# STM32N647 register map
File version: 1.0
CPU: CM55 r0p1, little endian, no MPU, FPU, vendor SysTick, 8 interrupt priority bits
Registers are 32-bit, read-write, reset 0x0 unless marked. A register's access mark holds for its fields unless they carry their own. Offsets are from the block's base; [hi:lo] are bit positions; {n}, {i} and the like mark numbered series.

## RCC (part 2 of 2) — Reset and clock control
Base 0x46028000
Same registers: RCC_S 0x56028000
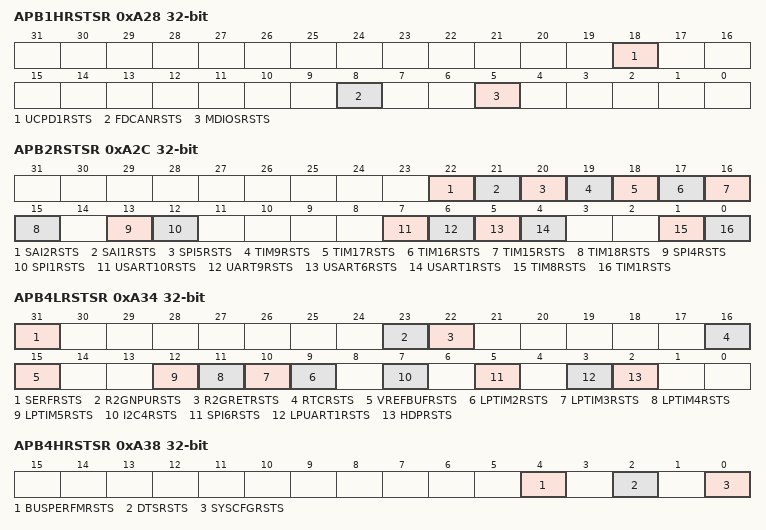
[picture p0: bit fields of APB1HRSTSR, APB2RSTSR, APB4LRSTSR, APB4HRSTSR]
0xA28 APB1HRSTSR wo — RCC APB1H reset register
  [18] UCPD1RSTS — UCPD1 reset
  [8] FDCANRSTS — FDCAN reset
  [5] MDIOSRSTS — MDIOS reset
0xA2C APB2RSTSR wo — RCC APB2 reset register
  [22] SAI2RSTS — SAI2 reset
  [21] SAI1RSTS — SAI1 reset
  [20] SPI5RSTS — SPI5 reset
  [19] TIM9RSTS — TIM9 reset
  [18] TIM17RSTS — TIM17 reset
  [17] TIM16RSTS — TIM16 reset
  [16] TIM15RSTS — TIM15 reset
  [15] TIM18RSTS — TIM18 reset
  [13] SPI4RSTS — SPI4 reset
  [12] SPI1RSTS — SPI1 reset
  [7] USART10RSTS — USART10 reset
  [6] UART9RSTS — UART9 reset
  [5] USART6RSTS — USART6 reset
  [4] USART1RSTS — USART1 reset
  [1] TIM8RSTS — TIM8 reset
  [0] TIM1RSTS — TIM1 reset
0xA34 APB4LRSTSR wo — RCC APB4L reset register
  [31] SERFRSTS — SERF reset
  [23] R2GNPURSTS — R2GNPU reset
  [22] R2GRETRSTS — R2GRET reset
  [16] RTCRSTS — RTC reset
  [15] VREFBUFRSTS — VREFBUF reset
  [n+7] LPTIM{n}RSTS (n=2..5) — LPTIM{n} reset
  [7] I2C4RSTS — I2C4 reset
  [5] SPI6RSTS — SPI6 reset
  [3] LPUART1RSTS — LPUART1 reset
  [2] HDPRSTS — HDP reset
0xA38 APB4HRSTSR wo — RCC APB4H reset register
  [4] BUSPERFMRSTS — BUSPERFM reset
  [2] DTSRSTS — DTS reset
  [0] SYSCFGRSTS — SYSCFG reset
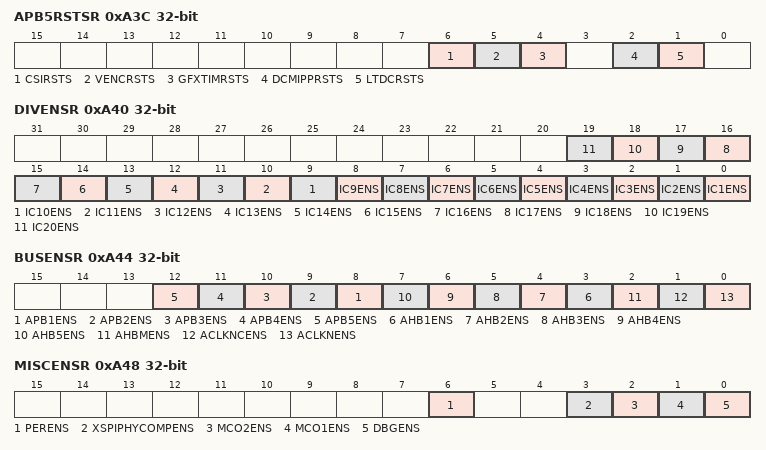
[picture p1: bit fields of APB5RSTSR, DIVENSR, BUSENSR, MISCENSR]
0xA3C APB5RSTSR wo — RCC APB5 reset register
  [6] CSIRSTS — CSI reset
  [5] VENCRSTS — VENC reset
  [4] GFXTIMRSTS — GFXTIM reset
  [2] DCMIPPRSTS — DCMIPP reset
  [1] LTDCRSTS — LTDC reset
0xA40 DIVENSR wo — RCC Divider enable register
  [n-1] IC{n}ENS (n=1..20) — IC{n} enable
0xA44 BUSENSR wo — RCC bus enable register
  [n+7] APB{n}ENS (n=1..5) — APB{n} enable
  [n+2] AHB{n}ENS (n=1..5) — AHB{n} enable
  [2] AHBMENS — AHBM enable
  [1] ACLKNCENS — ACLKNC enable
  [0] ACLKNENS — ACLKN enable
0xA48 MISCENSR wo — RCC miscellaneous enable register
  [6] PERENS — PER enable
  [3] XSPIPHYCOMPENS — XSPIPHYCOMP enable
  [2] MCO2ENS — MCO2 enable
  [1] MCO1ENS — MCO1 enable
  [0] DBGENS — DBG enable
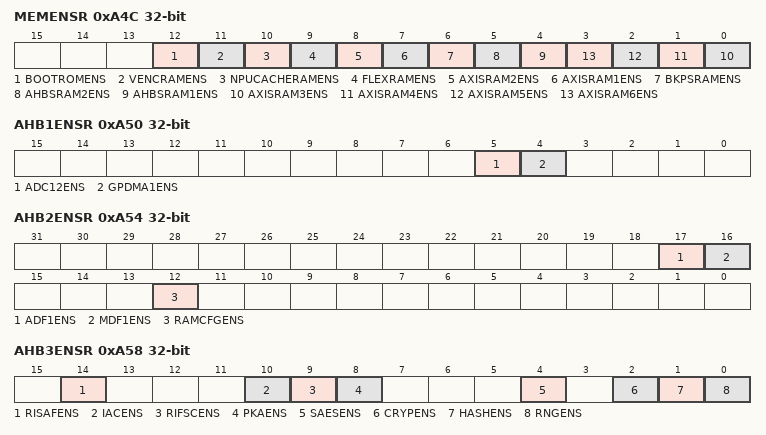
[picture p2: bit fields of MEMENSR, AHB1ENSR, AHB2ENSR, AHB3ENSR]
0xA4C MEMENSR wo — RCC memory enable register
  [12] BOOTROMENS — BOOTROM enable
  [11] VENCRAMENS — VENCRAM enable
  [10] NPUCACHERAMENS — NPUCACHERAM enable
  [9] FLEXRAMENS — FLEXRAM enable
  [8] AXISRAM2ENS — AXISRAM2 enable
  [7] AXISRAM1ENS — AXISRAM1 enable
  [6] BKPSRAMENS — BKPSRAM enable
  [5] AHBSRAM2ENS — AHBSRAM2 enable
  [4] AHBSRAM1ENS — AHBSRAM1 enable
  [n-3] AXISRAM{n}ENS (n=3..6) — AXISRAM{n} enable
0xA50 AHB1ENSR wo — RCC AHB1 enable register
  [5] ADC12ENS — ADC12 enable
  [4] GPDMA1ENS — GPDMA1 enable
0xA54 AHB2ENSR wo — RCC AHB2 enable register
  [17] ADF1ENS — ADF1 enable
  [16] MDF1ENS — MDF1 enable
  [12] RAMCFGENS — RAMCFG enable
0xA58 AHB3ENSR wo — RCC AHB3 enable register
  [14] RISAFENS — RISAF enable
  [10] IACENS — IAC enable
  [9] RIFSCENS — RIFSC enable
  [8] PKAENS — PKA enable
  [4] SAESENS — SAES enable
  [2] CRYPENS — CRYP enable
  [1] HASHENS — HASH enable
  [0] RNGENS — RNG enable
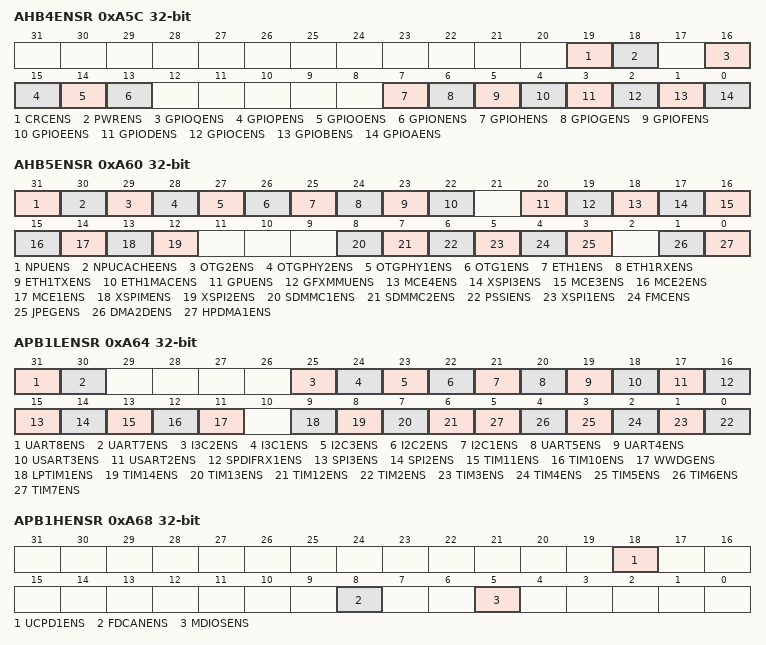
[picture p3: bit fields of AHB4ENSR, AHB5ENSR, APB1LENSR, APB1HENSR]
0xA5C AHB4ENSR wo — RCC AHB4 enable register
  [19] CRCENS — CRC enable
  [18] PWRENS — PWR enable
  [16] GPIOQENS — GPIOQ enable
  [15] GPIOPENS — GPIOP enable
  [14] GPIOOENS — GPIOO enable
  [13] GPIONENS — GPION enable
  [7] GPIOHENS — GPIOH enable
  [6] GPIOGENS — GPIOG enable
  [5] GPIOFENS — GPIOF enable
  [4] GPIOEENS — GPIOE enable
  [3] GPIODENS — GPIOD enable
  [2] GPIOCENS — GPIOC enable
  [1] GPIOBENS — GPIOB enable
  [0] GPIOAENS — GPIOA enable
0xA60 AHB5ENSR wo — RCC AHB5 enable register
  [31] NPUENS — NPU enable
  [30] NPUCACHEENS — NPUCACHE enable
  [29] OTG2ENS — OTG2 enable
  [28] OTGPHY2ENS — OTGPHY2 enable
  [27] OTGPHY1ENS — OTGPHY1 enable
  [26] OTG1ENS — OTG1 enable
  [25] ETH1ENS — ETH1 enable
  [24] ETH1RXENS — ETH1RX enable
  [23] ETH1TXENS — ETH1TX enable
  [22] ETH1MACENS — ETH1MAC enable
  [20] GPUENS — GPU enable
  [19] GFXMMUENS — GFXMMU enable
  [18] MCE4ENS — MCE4 enable
  [17] XSPI3ENS — XSPI3 enable
  [16] MCE3ENS — MCE3 enable
  [15] MCE2ENS — MCE2 enable
  [14] MCE1ENS — MCE1 enable
  [13] XSPIMENS — XSPIM enable
  [12] XSPI2ENS — XSPI2 enable
  [8] SDMMC1ENS — SDMMC1 enable
  [7] SDMMC2ENS — SDMMC2 enable
  [6] PSSIENS — PSSI enable
  [5] XSPI1ENS — XSPI1 enable
  [4] FMCENS — FMC enable
  [3] JPEGENS — JPEG enable
  [1] DMA2DENS — DMA2D enable
  [0] HPDMA1ENS — HPDMA1 enable
0xA64 APB1LENSR wo — RCC APB1L enable register
  [31] UART8ENS — UART8 enable
  [30] UART7ENS — UART7 enable
  [25] I3C2ENS — I3C2 enable
  [24] I3C1ENS — I3C1 enable
  [23] I2C3ENS — I2C3 enable
  [22] I2C2ENS — I2C2 enable
  [21] I2C1ENS — I2C1 enable
  [20] UART5ENS — UART5 enable
  [19] UART4ENS — UART4 enable
  [18] USART3ENS — USART3 enable
  [17] USART2ENS — USART2 enable
  [16] SPDIFRX1ENS — SPDIFRX1 enable
  [15] SPI3ENS — SPI3 enable
  [14] SPI2ENS — SPI2 enable
  [13] TIM11ENS — TIM11 enable
  [12] TIM10ENS — TIM10 enable
  [11] WWDGENS — WWDG enable
  [9] LPTIM1ENS — LPTIM1 enable
  [8] TIM14ENS — TIM14 enable
  [7] TIM13ENS — TIM13 enable
  [6] TIM12ENS — TIM12 enable
  [n-2] TIM{n}ENS (n=2..7) — TIM{n} enable
0xA68 APB1HENSR wo — RCC APB1H enable register
  [18] UCPD1ENS — UCPD1 enable
  [8] FDCANENS — FDCAN enable
  [5] MDIOSENS — MDIOS enable
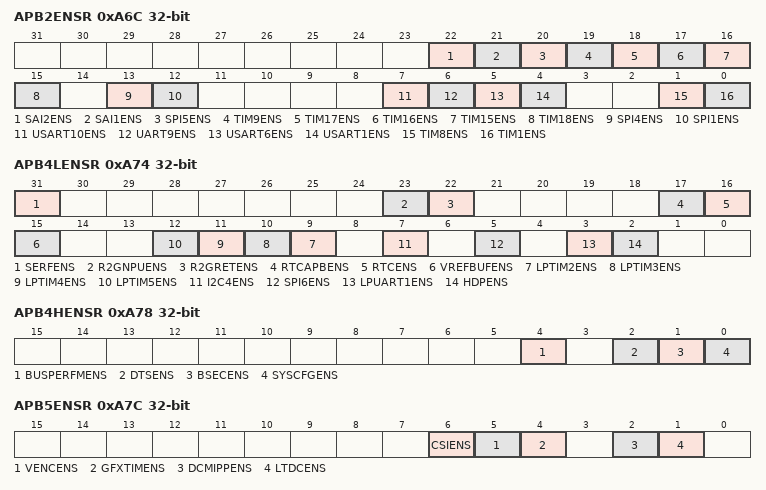
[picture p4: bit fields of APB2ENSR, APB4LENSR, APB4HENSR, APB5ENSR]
0xA6C APB2ENSR wo — RCC APB2 enable register
  [22] SAI2ENS — SAI2 enable
  [21] SAI1ENS — SAI1 enable
  [20] SPI5ENS — SPI5 enable
  [19] TIM9ENS — TIM9 enable
  [18] TIM17ENS — TIM17 enable
  [17] TIM16ENS — TIM16 enable
  [16] TIM15ENS — TIM15 enable
  [15] TIM18ENS — TIM18 enable
  [13] SPI4ENS — SPI4 enable
  [12] SPI1ENS — SPI1 enable
  [7] USART10ENS — USART10 enable
  [6] UART9ENS — UART9 enable
  [5] USART6ENS — USART6 enable
  [4] USART1ENS — USART1 enable
  [1] TIM8ENS — TIM8 enable
  [0] TIM1ENS — TIM1 enable
0xA70 APB3ENSR wo — RCC APB3 enable register
  [2] DFTENS — DFT enable
0xA74 APB4LENSR wo — RCC APB4L enable register
  [31] SERFENS — SERF enable
  [23] R2GNPUENS — R2GNPU enable
  [22] R2GRETENS — R2GRET enable
  [17] RTCAPBENS — RTCAPB enable
  [16] RTCENS — RTC enable
  [15] VREFBUFENS — VREFBUF enable
  [n+7] LPTIM{n}ENS (n=2..5) — LPTIM{n} enable
  [7] I2C4ENS — I2C4 enable
  [5] SPI6ENS — SPI6 enable
  [3] LPUART1ENS — LPUART1 enable
  [2] HDPENS — HDP enable
0xA78 APB4HENSR wo — RCC APB4H enable register
  [4] BUSPERFMENS — BUSPERFM enable
  [2] DTSENS — DTS enable
  [1] BSECENS — BSEC enable
  [0] SYSCFGENS — SYSCFG enable
0xA7C APB5ENSR wo — RCC APB5 enable register
  [6] CSIENS — CSI enable
  [5] VENCENS — VENC enable
  [4] GFXTIMENS — GFXTIM enable
  [2] DCMIPPENS — DCMIPP enable
  [1] LTDCENS — LTDC enable
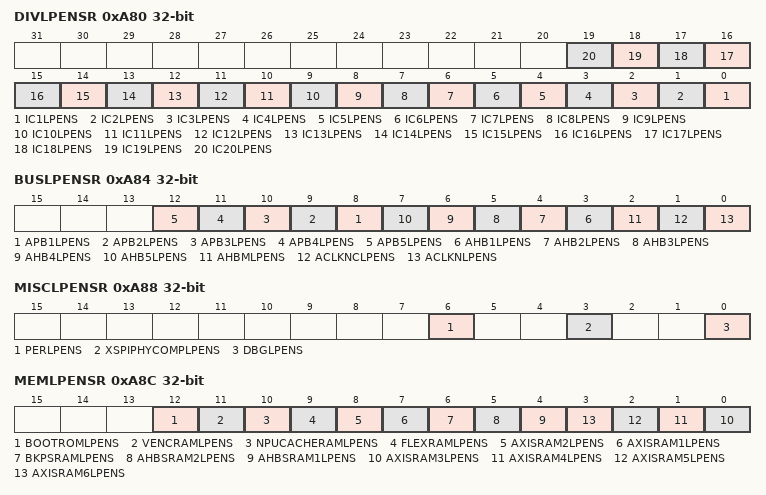
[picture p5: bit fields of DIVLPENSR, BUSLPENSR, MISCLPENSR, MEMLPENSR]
0xA80 DIVLPENSR wo — RCC divider Sleep enable register
  [n-1] IC{n}LPENS (n=1..20) — IC{n} sleep enable
0xA84 BUSLPENSR wo — RCC bus Sleep enable register
  [n+7] APB{n}LPENS (n=1..5) — APB{n} sleep enable
  [n+2] AHB{n}LPENS (n=1..5) — AHB{n} sleep enable
  [2] AHBMLPENS — AHBM sleep enable
  [1] ACLKNCLPENS — ACLKNC sleep enable
  [0] ACLKNLPENS — ACLKN sleep enable
0xA88 MISCLPENSR wo — RCC miscellaneous Sleep enable register
  [6] PERLPENS — PER sleep enable
  [3] XSPIPHYCOMPLPENS — XSPIPHYCOMP sleep enable
  [0] DBGLPENS — DBG sleep enable
0xA8C MEMLPENSR wo — RCC memory sleep enable register
  [12] BOOTROMLPENS — BOOTROM sleep enable
  [11] VENCRAMLPENS — VENCRAM sleep enable
  [10] NPUCACHERAMLPENS — NPUCACHERAM sleep enable
  [9] FLEXRAMLPENS — FLEXRAM sleep enable
  [8] AXISRAM2LPENS — AXISRAM2 sleep enable
  [7] AXISRAM1LPENS — AXISRAM1 sleep enable
  [6] BKPSRAMLPENS — BKPSRAM sleep enable
  [5] AHBSRAM2LPENS — AHBSRAM2 sleep enable
  [4] AHBSRAM1LPENS — AHBSRAM1 sleep enable
  [n-3] AXISRAM{n}LPENS (n=3..6) — AXISRAM{n} sleep enable
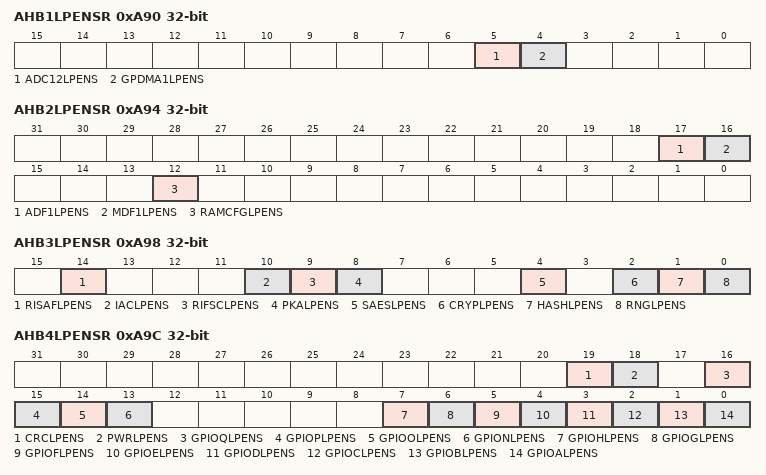
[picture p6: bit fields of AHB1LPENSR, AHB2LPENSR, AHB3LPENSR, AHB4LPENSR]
0xA90 AHB1LPENSR wo — RCC AHB1 Sleep enable register
  [5] ADC12LPENS — ADC12 sleep enable
  [4] GPDMA1LPENS — GPDMA1 sleep enable
0xA94 AHB2LPENSR wo — RCC AHB2 Sleep enable register
  [17] ADF1LPENS — ADF1 sleep enable
  [16] MDF1LPENS — MDF1 sleep enable
  [12] RAMCFGLPENS — RAMCFG sleep enable
0xA98 AHB3LPENSR wo — RCC AHB3 Sleep enable register
  [14] RISAFLPENS — RISAF sleep enable
  [10] IACLPENS — IAC sleep enable
  [9] RIFSCLPENS — RIFSC sleep enable
  [8] PKALPENS — PKA sleep enable
  [4] SAESLPENS — SAES sleep enable
  [2] CRYPLPENS — CRYP sleep enable
  [1] HASHLPENS — HASH sleep enable
  [0] RNGLPENS — RNG sleep enable
0xA9C AHB4LPENSR wo — RCC AHB4 Sleep enable register
  [19] CRCLPENS — CRC sleep enable
  [18] PWRLPENS — PWR sleep enable
  [16] GPIOQLPENS — GPIOQ sleep enable
  [15] GPIOPLPENS — GPIOP sleep enable
  [14] GPIOOLPENS — GPIOO sleep enable
  [13] GPIONLPENS — GPION sleep enable
  [7] GPIOHLPENS — GPIOH sleep enable
  [6] GPIOGLPENS — GPIOG sleep enable
  [5] GPIOFLPENS — GPIOF sleep enable
  [4] GPIOELPENS — GPIOE sleep enable
  [3] GPIODLPENS — GPIOD sleep enable
  [2] GPIOCLPENS — GPIOC sleep enable
  [1] GPIOBLPENS — GPIOB sleep enable
  [0] GPIOALPENS — GPIOA sleep enable
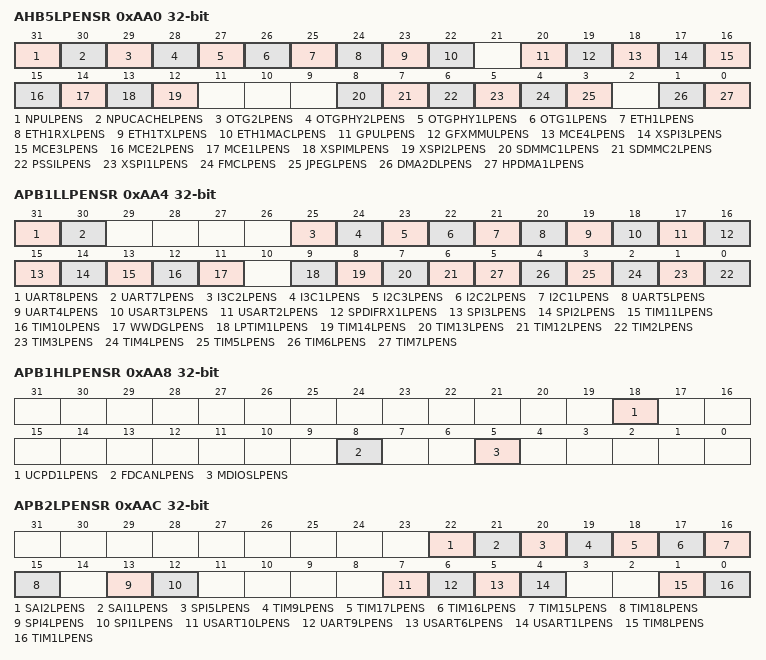
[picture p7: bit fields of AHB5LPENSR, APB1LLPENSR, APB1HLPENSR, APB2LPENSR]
0xAA0 AHB5LPENSR wo — RCC AHB5 Sleep enable register
  [31] NPULPENS — NPU sleep enable
  [30] NPUCACHELPENS — NPUCACHE sleep enable
  [29] OTG2LPENS — OTG2 sleep enable
  [28] OTGPHY2LPENS — OTGPHY2 sleep enable
  [27] OTGPHY1LPENS — OTGPHY1 sleep enable
  [26] OTG1LPENS — OTG1 sleep enable
  [25] ETH1LPENS — ETH1 sleep enable
  [24] ETH1RXLPENS — ETH1RX sleep enable
  [23] ETH1TXLPENS — ETH1TX sleep enable
  [22] ETH1MACLPENS — ETH1MAC sleep enable
  [20] GPULPENS — GPU sleep enable
  [19] GFXMMULPENS — GFXMMU sleep enable
  [18] MCE4LPENS — MCE4 sleep enable
  [17] XSPI3LPENS — XSPI3 sleep enable
  [16] MCE3LPENS — MCE3 sleep enable
  [15] MCE2LPENS — MCE2 sleep enable
  [14] MCE1LPENS — MCE1 sleep enable
  [13] XSPIMLPENS — XSPIM sleep enable
  [12] XSPI2LPENS — XSPI2 sleep enable
  [8] SDMMC1LPENS — SDMMC1 sleep enable
  [7] SDMMC2LPENS — SDMMC2 sleep enable
  [6] PSSILPENS — PSSI sleep enable
  [5] XSPI1LPENS — XSPI1 sleep enable
  [4] FMCLPENS — FMC sleep enable
  [3] JPEGLPENS — JPEG sleep enable
  [1] DMA2DLPENS — DMA2D sleep enable
  [0] HPDMA1LPENS — HPDMA1 sleep enable
0xAA4 APB1LLPENSR wo — RCC APB1L Sleep enable register
  [31] UART8LPENS — UART8 sleep enable
  [30] UART7LPENS — UART7 sleep enable
  [25] I3C2LPENS — I3C2 sleep enable
  [24] I3C1LPENS — I3C1 sleep enable
  [23] I2C3LPENS — I2C3 sleep enable
  [22] I2C2LPENS — I2C2 sleep enable
  [21] I2C1LPENS — I2C1 sleep enable
  [20] UART5LPENS — UART5 sleep enable
  [19] UART4LPENS — UART4 sleep enable
  [18] USART3LPENS — USART3 sleep enable
  [17] USART2LPENS — USART2 sleep enable
  [16] SPDIFRX1LPENS — SPDIFRX1 sleep enable
  [15] SPI3LPENS — SPI3 sleep enable
  [14] SPI2LPENS — SPI2 sleep enable
  [13] TIM11LPENS — TIM11 sleep enable
  [12] TIM10LPENS — TIM10 sleep enable
  [11] WWDGLPENS — WWDG sleep enable
  [9] LPTIM1LPENS — LPTIM1 sleep enable
  [8] TIM14LPENS — TIM14 sleep enable
  [7] TIM13LPENS — TIM13 sleep enable
  [6] TIM12LPENS — TIM12 sleep enable
  [n-2] TIM{n}LPENS (n=2..7) — TIM{n} sleep enable
0xAA8 APB1HLPENSR wo — RCC APB1H Sleep enable register
  [18] UCPD1LPENS — UCPD1 sleep enable
  [8] FDCANLPENS — FDCAN sleep enable
  [5] MDIOSLPENS — MDIOS sleep enable
0xAAC APB2LPENSR wo — RCC APB2 Sleep enable register
  [22] SAI2LPENS — SAI2 sleep enable
  [21] SAI1LPENS — SAI1 sleep enable
  [20] SPI5LPENS — SPI5 sleep enable
  [19] TIM9LPENS — TIM9 sleep enable
  [18] TIM17LPENS — TIM17 sleep enable
  [17] TIM16LPENS — TIM16 sleep enable
  [16] TIM15LPENS — TIM15 sleep enable
  [15] TIM18LPENS — TIM18 sleep enable
  [13] SPI4LPENS — SPI4 sleep enable
  [12] SPI1LPENS — SPI1 sleep enable
  [7] USART10LPENS — USART10 sleep enable
  [6] UART9LPENS — UART9 sleep enable
  [5] USART6LPENS — USART6 sleep enable
  [4] USART1LPENS — USART1 sleep enable
  [1] TIM8LPENS — TIM8 sleep enable
  [0] TIM1LPENS — TIM1 sleep enable
0xAB0 APB3LPENSR wo — RCC APB3 Sleep enable register
  [2] DFTLPENS — DFT sleep enable
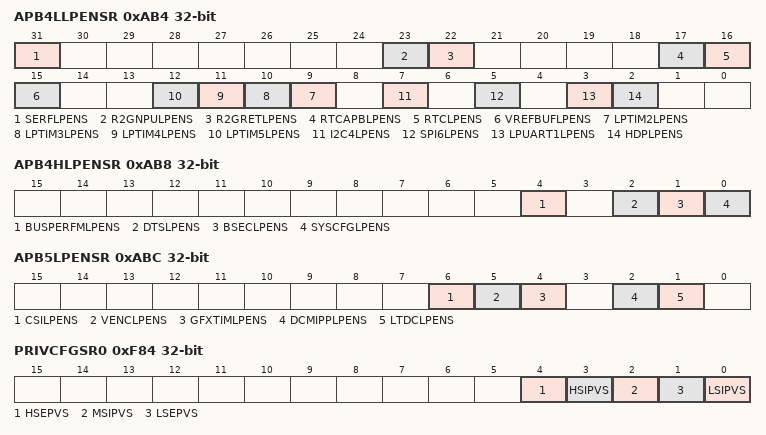
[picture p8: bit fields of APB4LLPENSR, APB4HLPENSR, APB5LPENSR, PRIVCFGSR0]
0xAB4 APB4LLPENSR wo — RCC APB4L Sleep enable register
  [31] SERFLPENS — SERF sleep enable
  [23] R2GNPULPENS — R2GNPU sleep enable
  [22] R2GRETLPENS — R2GRET sleep enable
  [17] RTCAPBLPENS — RTCAPB sleep enable
  [16] RTCLPENS — RTC sleep enable
  [15] VREFBUFLPENS — VREFBUF sleep enable
  [n+7] LPTIM{n}LPENS (n=2..5) — LPTIM{n} sleep enable
  [7] I2C4LPENS — I2C4 sleep enable
  [5] SPI6LPENS — SPI6 sleep enable
  [3] LPUART1LPENS — LPUART1 sleep enable
  [2] HDPLPENS — HDP sleep enable
0xAB8 APB4HLPENSR wo — RCC APB4H Sleep enable register
  [4] BUSPERFMLPENS — BUSPERFM sleep enable
  [2] DTSLPENS — DTS sleep enable
  [1] BSECLPENS — BSEC sleep enable
  [0] SYSCFGLPENS — SYSCFG sleep enable
0xABC APB5LPENSR wo — RCC APB5 Sleep enable register
  [6] CSILPENS — CSI sleep enable
  [5] VENCLPENS — VENC sleep enable
  [4] GFXTIMLPENS — GFXTIM sleep enable
  [2] DCMIPPLPENS — DCMIPP sleep enable
  [1] LTDCLPENS — LTDC sleep enable
0xF84 PRIVCFGSR0 wo — RCC oscillator privilege configuration register0
  [4] HSEPVS — Defines the privilege protection of the HSE configuration bits (enable, ready, divider).
  [3] HSIPVS — Defines the privilege protection of the HSI configuration bits (enable, ready, divider).
  [2] MSIPVS — Defines the privilege protection of the MSI configuration bits (enable, ready, divider).
  [1] LSEPVS — Defines the privilege protection of the LSE configuration bits (enable, ready, divider).
  [0] LSIPVS — Defines the privilege protection of the LSI configuration bits (enable, ready, divider).
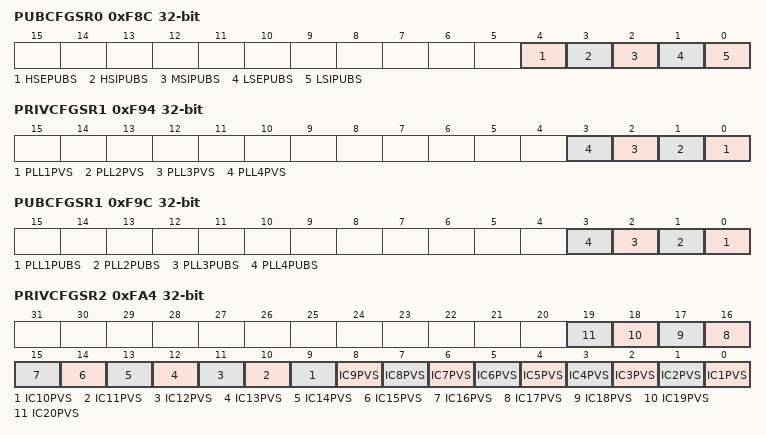
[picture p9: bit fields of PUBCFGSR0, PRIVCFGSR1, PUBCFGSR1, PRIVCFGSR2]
0xF8C PUBCFGSR0 wo — RCC oscillator public configuration register0
  [4] HSEPUBS — Defines the public protection of the HSE configuration bits (enable, ready, divider).
  [3] HSIPUBS — Defines the public protection of the HSI configuration bits (enable, ready, divider).
  [2] MSIPUBS — Defines the public protection of the MSI configuration bits (enable, ready, divider).
  [1] LSEPUBS — Defines the public protection of the LSE configuration bits (enable, ready, divider).
  [0] LSIPUBS — Defines the public protection of the LSI configuration bits (enable, ready, divider).
0xF94 PRIVCFGSR1 wo — RCC PLL privilege configuration register1
  [n-1] PLL{n}PVS (n=1..4) — Defines the privilege protection of the PLL{n} configuration bits (enable, ready, divider).
0xF9C PUBCFGSR1 wo — RCC PLL public configuration register1
  [n-1] PLL{n}PUBS (n=1..4) — Defines the public protection of the PLL{n} configuration bits (enable, ready, divider).
0xFA4 PRIVCFGSR2 wo — RCC divider privilege configuration register2
  [n-1] IC{n}PVS (n=1..20) — Defines the privilege protection of the IC{n} configuration bits (enable, ready, divider).
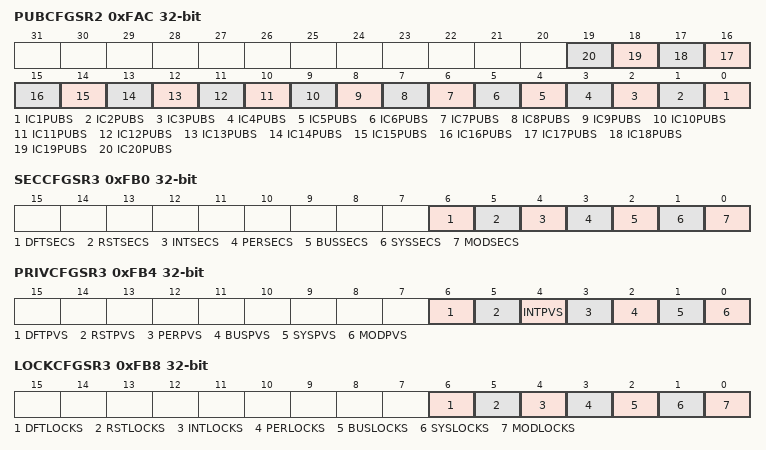
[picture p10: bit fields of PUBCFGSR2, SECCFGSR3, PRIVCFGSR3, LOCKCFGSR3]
0xFAC PUBCFGSR2 wo — RCC divider public configuration register2
  [n-1] IC{n}PUBS (n=1..20) — Defines the public protection of the IC{n} configuration bits (enable, ready, divider).
0xFB0 SECCFGSR3 wo — RCC system secure configuration register3
  [6] DFTSECS — Defines the secure protection of the DFT configuration bits (enable, ready, divider).
  [5] RSTSECS — Defines the secure protection of the RST configuration bits (enable, ready, divider).
  [4] INTSECS — Defines the secure protection of the INT configuration bits (enable, ready, divider).
  [3] PERSECS — Defines the secure protection of the PER configuration bits (enable, ready, divider).
  [2] BUSSECS — Defines the secure protection of the BUS configuration bits (enable, ready, divider).
  [1] SYSSECS — Defines the secure protection of the SYS configuration bits (enable, ready, divider).
  [0] MODSECS — Defines the secure protection of the MOD configuration bits (enable, ready, divider).
0xFB4 PRIVCFGSR3 wo — RCC system privilege configuration register3
  [6] DFTPVS — Defines the privilege protection of the DFT configuration bits (enable, ready, divider).
  [5] RSTPVS — Defines the privilege protection of the RST configuration bits (enable, ready, divider).
  [4] INTPVS — Defines the privilege protection of the INT configuration bits (enable, ready, divider).
  [3] PERPVS — Defines the privilege protection of the PER configuration bits (enable, ready, divider).
  [2] BUSPVS — Defines the privilege protection of the BUS configuration bits (enable, ready, divider).
  [1] SYSPVS — Defines the privilege protection of the SYS configuration bits (enable, ready, divider).
  [0] MODPVS — Defines the privilege protection of the MOD configuration bits (enable, ready, divider).
0xFB8 LOCKCFGSR3 wo — RCC system lock configuration register3
  [6] DFTLOCKS — Defines the lock protection of the DFT configuration bits (enable, ready, divider).
  [5] RSTLOCKS — Defines the lock protection of the RST configuration bits (enable, ready, divider).
  [4] INTLOCKS — Defines the lock protection of the INT configuration bits (enable, ready, divider).
  [3] PERLOCKS — Defines the lock protection of the PER configuration bits (enable, ready, divider).
  [2] BUSLOCKS — Defines the lock protection of the BUS configuration bits (enable, ready, divider).
  [1] SYSLOCKS — Defines the lock protection of the SYS configuration bits (enable, ready, divider).
  [0] MODLOCKS — Defines the lock protection of the MOD configuration bits (enable, ready, divider).
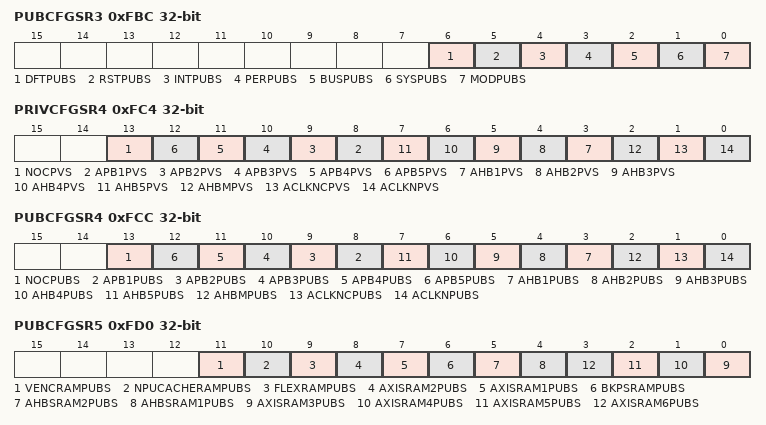
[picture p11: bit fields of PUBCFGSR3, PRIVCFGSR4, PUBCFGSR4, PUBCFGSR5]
0xFBC PUBCFGSR3 wo — RCC system public configuration register3
  [6] DFTPUBS — Defines the public protection of the DFT configuration bits (enable, ready, divider).
  [5] RSTPUBS — Defines the public protection of the RST configuration bits (enable, ready, divider).
  [4] INTPUBS — Defines the public protection of the INT configuration bits (enable, ready, divider).
  [3] PERPUBS — Defines the public protection of the PER configuration bits (enable, ready, divider).
  [2] BUSPUBS — Defines the public protection of the BUS configuration bits (enable, ready, divider).
  [1] SYSPUBS — Defines the public protection of the SYS configuration bits (enable, ready, divider).
  [0] MODPUBS — Defines the public protection of the MOD configuration bits (enable, ready, divider).
0xFC4 PRIVCFGSR4 wo — RCC privilege configuration register4
  [13] NOCPVS — Defines the privilege protection of the NOC configuration bits (enable, ready, divider).
  [n+7] APB{n}PVS (n=1..5) — Defines the privilege protection of the APB{n} configuration bits (enable, ready, divider).
  [n+2] AHB{n}PVS (n=1..5) — Defines the privilege protection of the AHB{n} configuration bits (enable, ready, divider).
  [2] AHBMPVS — Defines the privilege protection of the AHBM configuration bits (enable, ready, divider).
  [1] ACLKNCPVS — Defines the privilege protection of the ACLKNC configuration bits (enable, ready, divider).
  [0] ACLKNPVS — Defines the privilege protection of the ACLKN configuration bits (enable, ready, divider).
0xFCC PUBCFGSR4 wo — RCC public configuration register4
  [13] NOCPUBS — Defines the public protection of the NOC configuration bits (enable, ready, divider).
  [n+7] APB{n}PUBS (n=1..5) — Defines the public protection of the APB{n} configuration bits (enable, ready, divider).
  [n+2] AHB{n}PUBS (n=1..5) — Defines the public protection of the AHB{n} configuration bits (enable, ready, divider).
  [2] AHBMPUBS — Defines the public protection of the AHBM configuration bits (enable, ready, divider).
  [1] ACLKNCPUBS — Defines the public protection of the ACLKNC configuration bits (enable, ready, divider).
  [0] ACLKNPUBS — Defines the public protection of the ACLKN configuration bits (enable, ready, divider).
0xFD0 PUBCFGSR5 wo — RCC public configuration register4
  [11] VENCRAMPUBS — Defines the public protection of the VENCRAM configuration bits (enable, ready, divider).
  [10] NPUCACHERAMPUBS — Defines the public protection of the NPUCACHERAM configuration bits (enable, ready, divider).
  [9] FLEXRAMPUBS — Defines the public protection of the FLEXRAM configuration bits (enable, ready, divider).
  [8] AXISRAM2PUBS — Defines the public protection of the AXISRAM2 configuration bits (enable, ready, divider).
  [7] AXISRAM1PUBS — Defines the public protection of the AXISRAM1 configuration bits (enable, ready, divider).
  [6] BKPSRAMPUBS — Defines the public protection of the BKPSRAM configuration bits (enable, ready, divider).
  [5] AHBSRAM2PUBS — Defines the public protection of the AHBSRAM2 configuration bits (enable, ready, divider).
  [4] AHBSRAM1PUBS — Defines the public protection of the AHBSRAM1 configuration bits (enable, ready, divider).
  [n-3] AXISRAM{n}PUBS (n=3..6) — Defines the public protection of the AXISRAM{n} configuration bits (enable, ready, divider).
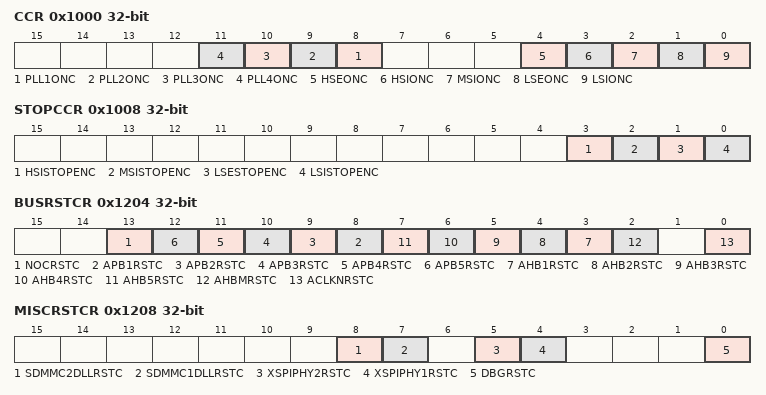
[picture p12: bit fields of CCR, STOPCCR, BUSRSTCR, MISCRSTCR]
0x1000 CCR wo — RCC control Clear register
  [n+7] PLL{n}ONC (n=1..4) — PLL{n} oscillator enable in Run/Sleep mode.
  [4] HSEONC — HSE oscillator enable in Run/Sleep mode.
  [3] HSIONC — HSI oscillator enable in Run/Sleep mode.
  [2] MSIONC — MSI oscillator enable in Run/Sleep mode.
  [1] LSEONC — LSE oscillator enable in Run/Sleep mode.
  [0] LSIONC — LSI oscillator enable in Run/Sleep mode.
0x1008 STOPCCR wo — RCC StopCCR configuration register
  [3] HSISTOPENC — HSI oscillator enable in Run/Sleep mode.
  [2] MSISTOPENC — MSI oscillator enable in Run/Sleep mode.
  [1] LSESTOPENC — LSE oscillator enable in Run/Sleep mode.
  [0] LSISTOPENC — LSI oscillator enable in Run/Sleep mode.
0x1204 BUSRSTCR wo — RCC bus reset register
  [13] NOCRSTC — NOC reset
  [n+7] APB{n}RSTC (n=1..5) — APB{n} reset
  [n+2] AHB{n}RSTC (n=1..5) — AHB{n} reset
  [2] AHBMRSTC — AHBM reset
  [0] ACLKNRSTC — ACLKN reset
0x1208 MISCRSTCR wo — RCC miscellaneous reset register
  [8] SDMMC2DLLRSTC — SDMMC2DLL reset
  [7] SDMMC1DLLRSTC — SDMMC1DLL reset
  [5] XSPIPHY2RSTC — XSPIPHY2 reset
  [4] XSPIPHY1RSTC — XSPIPHY1 reset
  [0] DBGRSTC — DBG reset
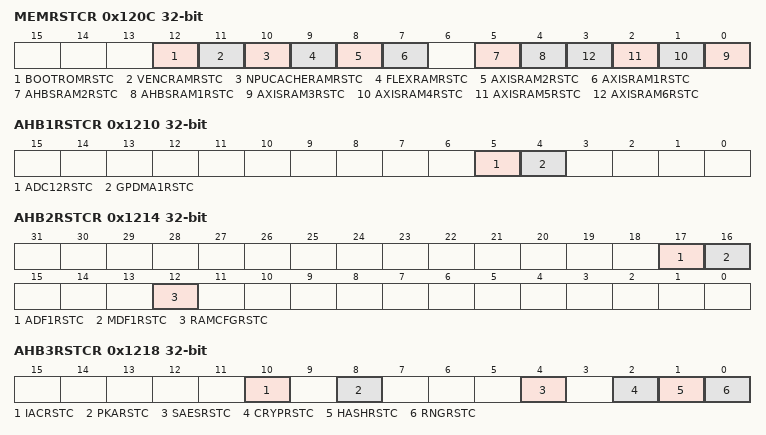
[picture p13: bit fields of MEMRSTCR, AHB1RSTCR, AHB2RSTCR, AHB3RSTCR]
0x120C MEMRSTCR wo — RCC memory reset register
  [12] BOOTROMRSTC — BOOTROM reset
  [11] VENCRAMRSTC — VENCRAM reset
  [10] NPUCACHERAMRSTC — NPUCACHERAM reset
  [9] FLEXRAMRSTC — FLEXRAM reset
  [8] AXISRAM2RSTC — AXISRAM2 reset
  [7] AXISRAM1RSTC — AXISRAM1 reset
  [5] AHBSRAM2RSTC — AHBSRAM2 reset
  [4] AHBSRAM1RSTC — AHBSRAM1 reset
  [n-3] AXISRAM{n}RSTC (n=3..6) — AXISRAM{n} reset
0x1210 AHB1RSTCR wo — RCC AHB1 reset register
  [5] ADC12RSTC — ADC12 reset
  [4] GPDMA1RSTC — GPDMA1 reset
0x1214 AHB2RSTCR wo — RCC AHB2 Reset register
  [17] ADF1RSTC — ADF1 reset
  [16] MDF1RSTC — MDF1 reset
  [12] RAMCFGRSTC — RAMCFG reset
0x1218 AHB3RSTCR wo — RCC AHB3 reset register
  [10] IACRSTC — IAC reset
  [8] PKARSTC — PKA reset
  [4] SAESRSTC — SAES reset
  [2] CRYPRSTC — CRYP reset
  [1] HASHRSTC — HASH reset
  [0] RNGRSTC — RNG reset
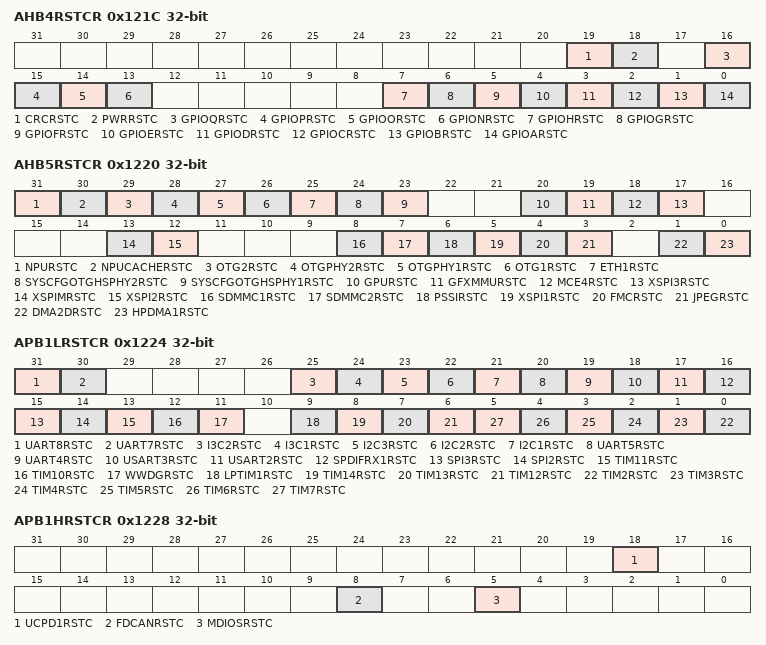
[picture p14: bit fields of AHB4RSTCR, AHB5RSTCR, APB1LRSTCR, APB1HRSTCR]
0x121C AHB4RSTCR wo — RCC AHB4 reset register
  [19] CRCRSTC — CRC reset
  [18] PWRRSTC — PWR reset
  [16] GPIOQRSTC — GPIOQ reset
  [15] GPIOPRSTC — GPIOP reset
  [14] GPIOORSTC — GPIOO reset
  [13] GPIONRSTC — GPION reset
  [7] GPIOHRSTC — GPIOH reset
  [6] GPIOGRSTC — GPIOG reset
  [5] GPIOFRSTC — GPIOF reset
  [4] GPIOERSTC — GPIOE reset
  [3] GPIODRSTC — GPIOD reset
  [2] GPIOCRSTC — GPIOC reset
  [1] GPIOBRSTC — GPIOB reset
  [0] GPIOARSTC — GPIOA reset
0x1220 AHB5RSTCR wo — RCC AHB5 reset register
  [31] NPURSTC — NPU reset
  [30] NPUCACHERSTC — NPUCACHE reset
  [29] OTG2RSTC — OTG2 reset
  [28] OTGPHY2RSTC — OTGPHY2 reset
  [27] OTGPHY1RSTC — OTGPHY1 reset
  [26] OTG1RSTC — OTG1 reset
  [25] ETH1RSTC — ETH1 reset
  [24] SYSCFGOTGHSPHY2RSTC — SYSCFGOTGHSPHY2 reset
  [23] SYSCFGOTGHSPHY1RSTC — SYSCFGOTGHSPHY1 reset
  [20] GPURSTC — GPU reset
  [19] GFXMMURSTC — GFXMMU reset
  [18] MCE4RSTC — MCE4 reset
  [17] XSPI3RSTC — XSPI3 reset
  [13] XSPIMRSTC — XSPIM reset
  [12] XSPI2RSTC — XSPI2 reset
  [8] SDMMC1RSTC — SDMMC1 reset
  [7] SDMMC2RSTC — SDMMC2 reset
  [6] PSSIRSTC — PSSI reset
  [5] XSPI1RSTC — XSPI1 reset
  [4] FMCRSTC — FMC reset
  [3] JPEGRSTC — JPEG reset
  [1] DMA2DRSTC — DMA2D reset
  [0] HPDMA1RSTC — HPDMA1 reset
0x1224 APB1LRSTCR wo — RCC APB1L reset register
  [31] UART8RSTC — UART8 reset
  [30] UART7RSTC — UART7 reset
  [25] I3C2RSTC — I3C2 reset
  [24] I3C1RSTC — I3C1 reset
  [23] I2C3RSTC — I2C3 reset
  [22] I2C2RSTC — I2C2 reset
  [21] I2C1RSTC — I2C1 reset
  [20] UART5RSTC — UART5 reset
  [19] UART4RSTC — UART4 reset
  [18] USART3RSTC — USART3 reset
  [17] USART2RSTC — USART2 reset
  [16] SPDIFRX1RSTC — SPDIFRX1 reset
  [15] SPI3RSTC — SPI3 reset
  [14] SPI2RSTC — SPI2 reset
  [13] TIM11RSTC — TIM11 reset
  [12] TIM10RSTC — TIM10 reset
  [11] WWDGRSTC — WWDG reset
  [9] LPTIM1RSTC — LPTIM1 reset
  [8] TIM14RSTC — TIM14 reset
  [7] TIM13RSTC — TIM13 reset
  [6] TIM12RSTC — TIM12 reset
  [n-2] TIM{n}RSTC (n=2..7) — TIM{n} reset
0x1228 APB1HRSTCR wo — RCC APB1H reset register
  [18] UCPD1RSTC — UCPD1 reset
  [8] FDCANRSTC — FDCAN reset
  [5] MDIOSRSTC — MDIOS reset
0x122C APB2RSTCR wo — RCC APB2 reset register
  [22] SAI2RSTC — SAI2 reset
  [21] SAI1RSTC — SAI1 reset
  [20] SPI5RSTC — SPI5 reset
  [19] TIM9RSTC — TIM9 reset
  [18] TIM17RSTC — TIM17 reset
  [17] TIM16RSTC — TIM16 reset
  [16] TIM15RSTC — TIM15 reset
  [15] TIM18RSTC — TIM18 reset
  [13] SPI4RSTC — SPI4 reset
  [12] SPI1RSTC — SPI1 reset
  [7] USART10RSTC — USART10 reset
  [6] UART9RSTC — UART9 reset
  [5] USART6RSTC — USART6 reset
  [4] USART1RSTC — USART1 reset
  [1] TIM8RSTC — TIM8 reset
  [0] TIM1RSTC — TIM1 reset
0x1234 APB4LRSTCR wo — RCC APB4L reset register
  [31] SERFRSTC — SERF reset
  [23] R2GNPURSTC — R2GNPU reset
  [22] R2GRETRSTC — R2GRET reset
  [16] RTCRSTC — RTC reset
  [15] VREFBUFRSTC — VREFBUF reset
  [n+7] LPTIM{n}RSTC (n=2..5) — LPTIM{n} reset
  [7] I2C4RSTC — I2C4 reset
  [5] SPI6RSTC — SPI6 reset
  [3] LPUART1RSTC — LPUART1 reset
  [2] HDPRSTC — HDP reset
0x1238 APB4HRSTCR wo — RCC APB4H reset register
  [4] BUSPERFMRSTC — BUSPERFM reset
  [2] DTSRSTC — DTS reset
  [0] SYSCFGRSTC — SYSCFG reset
0x123C APB5RSTCR wo — RCC APB5 reset register
  [6] CSIRSTC — CSI reset
  [5] VENCRSTC — VENC reset
  [4] GFXTIMRSTC — GFXTIM reset
  [2] DCMIPPRSTC — DCMIPP reset
  [1] LTDCRSTC — LTDC reset
0x1240 DIVENCR wo — RCC divider enable register
  [n-1] IC{n}ENC (n=1..20) — IC{n} enable
0x1244 BUSENCR wo — RCC bus enable register
  [n+7] APB{n}ENC (n=1..5) — APB{n} enable
  [n+2] AHB{n}ENC (n=1..5) — AHB{n} enable
  [2] AHBMENC — AHBM enable
  [1] ACLKNCENC — ACLKNC enable
  [0] ACLKNENC — ACLKN enable
0x1248 MISCENCR wo — RCC miscellaneous enable register
  [6] PERENC — PER enable
  [3] XSPIPHYCOMPENC — XSPIPHYCOMP enable
  [2] MCO2ENC — MCO2 enable
  [1] MCO1ENC — MCO1 enable
  [0] DBGENC — DBG enable
0x124C MEMENCR wo — RCC memory enable register
  [12] BOOTROMENC — BOOTROM enable
  [11] VENCRAMENC — VENCRAM enable
  [10] NPUCACHERAMENC — NPUCACHERAM enable
  [9] FLEXRAMENC — FLEXRAM enable
  [8] AXISRAM2ENC — AXISRAM2 enable
  [7] AXISRAM1ENC — AXISRAM1 enable
  [6] BKPSRAMENC — BKPSRAM enable
  [5] AHBSRAM2ENC — AHBSRAM2 enable
  [4] AHBSRAM1ENC — AHBSRAM1 enable
  [n-3] AXISRAM{n}ENC (n=3..6) — AXISRAM{n} enable
0x1250 AHB1ENCR wo — RCC AHB1 enable register
  [5] ADC12ENC — ADC12 enable
  [4] GPDMA1ENC — GPDMA1 enable
0x1254 AHB2ENCR wo — RCC AHB2 enable register
  [17] ADF1ENC — ADF1 enable
  [16] MDF1ENC — MDF1 enable
  [12] RAMCFGENC — RAMCFG enable
0x1258 AHB3ENCR wo — RCC AHB3 enable register
  [14] RISAFENC — RISAF enable
  [10] IACENC — IAC enable
  [9] RIFSCENC — RIFSC enable
  [8] PKAENC — PKA enable
  [4] SAESENC — SAES enable
  [2] CRYPENC — CRYP enable
  [1] HASHENC — HASH enable
  [0] RNGENC — RNG enable
0x125C AHB4ENCR wo — RCC AHB4 enable register
  [19] CRCENC — CRC enable
  [18] PWRENC — PWR enable
  [16] GPIOQENC — GPIOQ enable
  [15] GPIOPENC — GPIOP enable
  [14] GPIOOENC — GPIOO enable
  [13] GPIONENC — GPION enable
  [7] GPIOHENC — GPIOH enable
  [6] GPIOGENC — GPIOG enable
  [5] GPIOFENC — GPIOF enable
  [4] GPIOEENC — GPIOE enable
  [3] GPIODENC — GPIOD enable
  [2] GPIOCENC — GPIOC enable
  [1] GPIOBENC — GPIOB enable
  [0] GPIOAENC — GPIOA enable
0x1260 AHB5ENCR wo — RCC AHB5 enable register
  [31] NPUENC — NPU enable
  [30] NPUCACHEENC — NPUCACHE enable
  [29] OTG2ENC — OTG2 enable
  [28] OTGPHY2ENC — OTGPHY2 enable
  [27] OTGPHY1ENC — OTGPHY1 enable
  [26] OTG1ENC — OTG1 enable
  [25] ETH1ENC — ETH1 enable
  [24] ETH1RXENC — ETH1RX enable
  [23] ETH1TXENC — ETH1TX enable
  [22] ETH1MACENC — ETH1MAC enable
  [20] GPUENC — GPU enable
  [19] GFXMMUENC — GFXMMU enable
  [18] MCE4ENC — MCE4 enable
  [17] XSPI3ENC — XSPI3 enable
  [16] MCE3ENC — MCE3 enable
  [15] MCE2ENC — MCE2 enable
  [14] MCE1ENC — MCE1 enable
  [13] XSPIMENC — XSPIM enable
  [12] XSPI2ENC — XSPI2 enable
  [8] SDMMC1ENC — SDMMC1 enable
  [7] SDMMC2ENC — SDMMC2 enable
  [6] PSSIENC — PSSI enable
  [5] XSPI1ENC — XSPI1 enable
  [4] FMCENC — FMC enable
  [3] JPEGENC — JPEG enable
  [1] DMA2DENC — DMA2D enable
  [0] HPDMA1ENC — HPDMA1 enable
0x1264 APB1LENCR wo — RCC APB1L enable register
  [31] UART8ENC — UART8 enable
  [30] UART7ENC — UART7 enable
  [25] I3C2ENC — I3C2 enable
  [24] I3C1ENC — I3C1 enable
  [23] I2C3ENC — I2C3 enable
  [22] I2C2ENC — I2C2 enable
  [21] I2C1ENC — I2C1 enable
  [20] UART5ENC — UART5 enable
  [19] UART4ENC — UART4 enable
  [18] USART3ENC — USART3 enable
  [17] USART2ENC — USART2 enable
  [16] SPDIFRX1ENC — SPDIFRX1 enable
  [15] SPI3ENC — SPI3 enable
  [14] SPI2ENC — SPI2 enable
  [13] TIM11ENC — TIM11 enable
  [12] TIM10ENC — TIM10 enable
  [9] LPTIM1ENC — LPTIM1 enable
  [8] TIM14ENC — TIM14 enable
  [7] TIM13ENC — TIM13 enable
  [6] TIM12ENC — TIM12 enable
  [n-2] TIM{n}ENC (n=2..7) — TIM{n} enable
0x1268 APB1HENCR wo — RCC APB1H enable register
  [18] UCPD1ENC — UCPD1 enable
  [8] FDCANENC — FDCAN enable
  [5] MDIOSENC — MDIOS enable
0x126C APB2ENCR wo — RCC APB2 enable register
  [22] SAI2ENC — SAI2 enable
  [21] SAI1ENC — SAI1 enable
  [20] SPI5ENC — SPI5 enable
  [19] TIM9ENC — TIM9 enable
  [18] TIM17ENC — TIM17 enable
  [17] TIM16ENC — TIM16 enable
  [16] TIM15ENC — TIM15 enable
  [15] TIM18ENC — TIM18 enable
  [13] SPI4ENC — SPI4 enable
  [12] SPI1ENC — SPI1 enable
  [7] USART10ENC — USART10 enable
  [6] UART9ENC — UART9 enable
  [5] USART6ENC — USART6 enable
  [4] USART1ENC — USART1 enable
  [1] TIM8ENC — TIM8 enable
  [0] TIM1ENC — TIM1 enable
0x1270 APB3ENCR wo — RCC APB3 enable register
  [2] DFTENC — DFT enable
0x1274 APB4LENCR wo — RCC APB4L enable register
  [31] SERFENC — SERF enable
  [23] R2GNPUENC — R2GNPU enable
  [22] R2GRETENC — R2GRET enable
  [17] RTCAPBENC — RTCAPB enable
  [16] RTCENC — RTC enable
  [15] VREFBUFENC — VREFBUF enable
  [n+7] LPTIM{n}ENC (n=2..5) — LPTIM{n} enable
  [7] I2C4ENC — I2C4 enable
  [5] SPI6ENC — SPI6 enable
  [3] LPUART1ENC — LPUART1 enable
  [2] HDPENC — HDP enable
0x1278 APB4HENCR wo — RCC APB4H enable register
  [4] BUSPERFMENC — BUSPERFM enable
  [2] DTSENC — DTS enable
  [1] BSECENC — BSEC enable
  [0] SYSCFGENC — SYSCFG enable
0x127C APB5ENCR wo — RCC APB5 enable register
  [6] CSIENC — CSI enable
  [5] VENCENC — VENC enable
  [4] GFXTIMENC — GFXTIM enable
  [2] DCMIPPENC — DCMIPP enable
  [1] LTDCENC — LTDC enable
0x1280 DIVLPENCR wo — RCC divider Sleep enable register
  [n-1] IC{n}LPENC (n=1..20) — IC{n} sleep enable
0x1284 BUSLPENCR wo — RCC bus Sleep enable register
  [n+7] APB{n}LPENC (n=1..5) — APB{n} sleep enable
  [n+2] AHB{n}LPENC (n=1..5) — AHB{n} sleep enable
  [2] AHBMLPENC — AHBM sleep enable
  [1] ACLKNCLPENC — ACLKNC sleep enable
  [0] ACLKNLPENC — ACLKN sleep enable
0x1288 MISCLPENCR wo — RCC miscellaneous Sleep enable register
  [6] PERLPENC — PER sleep enable
  [3] XSPIPHYCOMPLPENC — XSPIPHYCOMP sleep enable
  [0] DBGLPENC — DBG sleep enable
0x128C MEMLPENCR wo — RCC memory Sleep enable register
  [12] BOOTROMLPENC — BOOTROM sleep enable
  [11] VENCRAMLPENC — VENCRAM sleep enable
  [10] NPUCACHERAMLPENC — NPUCACHERAM sleep enable
  [9] FLEXRAMLPENC — FLEXRAM sleep enable
  [8] AXISRAM2LPENC — AXISRAM2 sleep enable
  [7] AXISRAM1LPENC — AXISRAM1 sleep enable
  [6] BKPSRAMLPENC — BKPSRAM sleep enable
  [5] AHBSRAM2LPENC — AHBSRAM2 sleep enable
  [4] AHBSRAM1LPENC — AHBSRAM1 sleep enable
  [n-3] AXISRAM{n}LPENC (n=3..6) — AXISRAM{n} sleep enable
0x1290 AHB1LPENCR wo — RCC AHB1 Sleep enable register
  [5] ADC12LPENC — ADC12 sleep enable
  [4] GPDMA1LPENC — GPDMA1 sleep enable
0x1294 AHB2LPENCR wo — RCC AHB2 Sleep enable register
  [17] ADF1LPENC — ADF1 sleep enable
  [16] MDF1LPENC — MDF1 sleep enable
  [12] RAMCFGLPENC — RAMCFG sleep enable
0x1298 AHB3LPENCR wo — RCC AHB3 Sleep enable register
  [14] RISAFLPENC — RISAF sleep enable
  [10] IACLPENC — IAC sleep enable
  [9] RIFSCLPENC — RIFSC sleep enable
  [8] PKALPENC — PKA sleep enable
  [4] SAESLPENC — SAES sleep enable
  [2] CRYPLPENC — CRYP sleep enable
  [1] HASHLPENC — HASH sleep enable
  [0] RNGLPENC — RNG sleep enable
0x129C AHB4LPENCR wo — RCC AHB4 Sleep enable register
  [19] CRCLPENC — CRC sleep enable
  [18] PWRLPENC — PWR sleep enable
  [16] GPIOQLPENC — GPIOQ sleep enable
  [15] GPIOPLPENC — GPIOP sleep enable
  [14] GPIOOLPENC — GPIOO sleep enable
  [13] GPIONLPENC — GPION sleep enable
  [7] GPIOHLPENC — GPIOH sleep enable
  [6] GPIOGLPENC — GPIOG sleep enable
  [5] GPIOFLPENC — GPIOF sleep enable
  [4] GPIOELPENC — GPIOE sleep enable
  [3] GPIODLPENC — GPIOD sleep enable
  [2] GPIOCLPENC — GPIOC sleep enable
  [1] GPIOBLPENC — GPIOB sleep enable
  [0] GPIOALPENC — GPIOA sleep enable
0x12A0 AHB5LPENCR wo — RCC AHB5 Sleep enable register
  [31] NPULPENC — NPU sleep enable
  [30] NPUCACHELPENC — NPUCACHE sleep enable
  [29] OTG2LPENC — OTG2 sleep enable
  [28] OTGPHY2LPENC — OTGPHY2 sleep enable
  [27] OTGPHY1LPENC — OTGPHY1 sleep enable
  [26] OTG1LPENC — OTG1 sleep enable
  [25] ETH1LPENC — ETH1 sleep enable
  [24] ETH1RXLPENC — ETH1RX sleep enable
  [23] ETH1TXLPENC — ETH1TX sleep enable
  [22] ETH1MACLPENC — ETH1MAC sleep enable
  [20] GPULPENC — GPU sleep enable
  [19] GFXMMULPENC — GFXMMU sleep enable
  [18] MCE4LPENC — MCE4 sleep enable
  [17] XSPI3LPENC — XSPI3 sleep enable
  [16] MCE3LPENC — MCE3 sleep enable
  [15] MCE2LPENC — MCE2 sleep enable
  [14] MCE1LPENC — MCE1 sleep enable
  [13] XSPIMLPENC — XSPIM sleep enable
  [12] XSPI2LPENC — XSPI2 sleep enable
  [8] SDMMC1LPENC — SDMMC1 sleep enable
  [7] SDMMC2LPENC — SDMMC2 sleep enable
  [6] PSSILPENC — PSSI sleep enable
  [5] XSPI1LPENC — XSPI1 sleep enable
  [4] FMCLPENC — FMC sleep enable
  [3] JPEGLPENC — JPEG sleep enable
  [1] DMA2DLPENC — DMA2D sleep enable
  [0] HPDMA1LPENC — HPDMA1 sleep enable
0x12A4 APB1LLPENCR wo — RCC APB1L Sleep enable register
  [31] UART8LPENC — UART8 sleep enable
  [30] UART7LPENC — UART7 sleep enable
  [25] I3C2LPENC — I3C2 sleep enable
  [24] I3C1LPENC — I3C1 sleep enable
  [23] I2C3LPENC — I2C3 sleep enable
  [22] I2C2LPENC — I2C2 sleep enable
  [21] I2C1LPENC — I2C1 sleep enable
  [20] UART5LPENC — UART5 sleep enable
  [19] UART4LPENC — UART4 sleep enable
  [18] USART3LPENC — USART3 sleep enable
  [17] USART2LPENC — USART2 sleep enable
  [16] SPDIFRX1LPENC — SPDIFRX1 sleep enable
  [15] SPI3LPENC — SPI3 sleep enable
  [14] SPI2LPENC — SPI2 sleep enable
  [13] TIM11LPENC — TIM11 sleep enable
  [12] TIM10LPENC — TIM10 sleep enable
  [11] WWDGLPENC — WWDG sleep enable
  [9] LPTIM1LPENC — LPTIM1 sleep enable
  [8] TIM14LPENC — TIM14 sleep enable
  [7] TIM13LPENC — TIM13 sleep enable
  [6] TIM12LPENC — TIM12 sleep enable
  [n-2] TIM{n}LPENC (n=2..7) — TIM{n} sleep enable
0x12A8 APB1HLPENCR wo — RCC APB1H Sleep enable register
  [18] UCPD1LPENC — UCPD1 sleep enable
  [8] FDCANLPENC — FDCAN sleep enable
  [5] MDIOSLPENC — MDIOS sleep enable
0x12AC APB2LPENCR wo — RCC APB2 Sleep enable register
  [22] SAI2LPENC — SAI2 sleep enable
  [21] SAI1LPENC — SAI1 sleep enable
  [20] SPI5LPENC — SPI5 sleep enable
  [19] TIM9LPENC — TIM9 sleep enable
  [18] TIM17LPENC — TIM17 sleep enable
  [17] TIM16LPENC — TIM16 sleep enable
  [16] TIM15LPENC — TIM15 sleep enable
  [15] TIM18LPENC — TIM18 sleep enable
  [13] SPI4LPENC — SPI4 sleep enable
  [12] SPI1LPENC — SPI1 sleep enable
  [7] USART10LPENC — USART10 sleep enable
  [6] UART9LPENC — UART9 sleep enable
  [5] USART6LPENC — USART6 sleep enable
  [4] USART1LPENC — USART1 sleep enable
  [1] TIM8LPENC — TIM8 sleep enable
  [0] TIM1LPENC — TIM1 sleep enable
0x12B0 APB3LPENCR wo — RCC APB3 Sleep enable register
  [2] DFTLPENC — DFT sleep enable
0x12B4 APB4LLPENCR wo — RCC APB4L Sleep enable register
  [31] SERFLPENC — SERF sleep enable
  [23] R2GNPULPENC — R2GNPU sleep enable
  [22] R2GRETLPENC — R2GRET sleep enable
  [17] RTCAPBLPENC — RTCAPB sleep enable
  [16] RTCLPENC — RTC sleep enable
  [15] VREFBUFLPENC — VREFBUF sleep enable
  [n+7] LPTIM{n}LPENC (n=2..5) — LPTIM{n} sleep enable
  [7] I2C4LPENC — I2C4 sleep enable
  [5] SPI6LPENC — SPI6 sleep enable
  [3] LPUART1LPENC — LPUART1 sleep enable
  [2] HDPLPENC — HDP sleep enable
0x12B8 APB4HLPENCR wo — RCC APB4H Sleep enable register
  [4] BUSPERFMLPENC — BUSPERFM sleep enable
  [2] DTSLPENC — DTS sleep enable
  [1] BSECLPENC — BSEC sleep enable
  [0] SYSCFGLPENC — SYSCFG sleep enable
0x12BC APB5LPENCR wo — RCC APB5 Sleep enable register
  [6] CSILPENC — CSI sleep enable
  [5] VENCLPENC — VENC sleep enable
  [4] GFXTIMLPENC — GFXTIM sleep enable
  [2] DCMIPPLPENC — DCMIPP sleep enable
  [1] LTDCLPENC — LTDC sleep enable
0x1784 PRIVCFGCR0 wo — RCC oscillator privilege configuration register0
  [4] HSEPVC — Defines the privilege protection of the HSE configuration bits (enable, ready, divider).
  [3] HSIPVC — Defines the privilege protection of the HSI configuration bits (enable, ready, divider).
  [2] MSIPVC — Defines the privilege protection of the MSI configuration bits (enable, ready, divider).
  [1] LSEPVC — Defines the privilege protection of the LSE configuration bits (enable, ready, divider).
  [0] LSIPVC — Defines the privilege protection of the LSI configuration bits (enable, ready, divider).
0x178C PUBCFGCR0 wo — RCC oscillator public configuration register0
  [4] HSEPUBC — Defines the public protection of the HSE configuration bits (enable, ready, divider).
  [3] HSIPUBC — Defines the public protection of the HSI configuration bits (enable, ready, divider).
  [2] MSIPUBC — Defines the public protection of the MSI configuration bits (enable, ready, divider).
  [1] LSEPUBC — Defines the public protection of the LSE configuration bits (enable, ready, divider).
  [0] LSIPUBC — Defines the public protection of the LSI configuration bits (enable, ready, divider).
0x1794 PRIVCFGCR1 wo — RCC PLL privilege configuration register1
  [n-1] PLL{n}PVC (n=1..4) — Defines the privilege protection of the PLL{n} configuration bits (enable, ready, divider).
0x179C PUBCFGCR1 wo — RCC PLL public configuration register1
  [n-1] PLL{n}PUBC (n=1..4) — Defines the public protection of the PLL{n} configuration bits (enable, ready, divider).
0x17A4 PRIVCFGCR2 wo — RCC divider privilege configuration register2
  [n-1] IC{n}PVC (n=1..20) — Defines the privilege protection of the IC{n} configuration bits (enable, ready, divider).
0x17AC PUBCFGCR2 wo — RCC divider public configuration register2
  [n-1] IC{n}PUBC (n=1..20) — Defines the public protection of the IC{n} configuration bits (enable, ready, divider).
0x17B4 PRIVCFGCR3 wo — RCC system privilege configuration register3
  [6] DFTPVC — Defines the privilege protection of the DFT configuration bits (enable, ready, divider).
  [5] RSTPVC — Defines the privilege protection of the RST configuration bits (enable, ready, divider).
  [4] INTPVC — Defines the privilege protection of the INT configuration bits (enable, ready, divider).
  [3] PERPVC — Defines the privilege protection of the PER configuration bits (enable, ready, divider).
  [2] BUSPVC — Defines the privilege protection of the BUS configuration bits (enable, ready, divider).
  [1] SYSPVC — Defines the privilege protection of the SYS configuration bits (enable, ready, divider).
  [0] MODPVC — Defines the privilege protection of the MOD configuration bits (enable, ready, divider).
0x17BC PUBCFGCR3 wo — RCC system public configuration register3
  [6] DFTPUBC — Defines the public protection of the DFT configuration bits (enable, ready, divider).
  [5] RSTPUBC — Defines the public protection of the RST configuration bits (enable, ready, divider).
  [4] INTPUBC — Defines the public protection of the INT configuration bits (enable, ready, divider).
  [3] PERPUBC — Defines the public protection of the PER configuration bits (enable, ready, divider).
  [2] BUSPUBC — Defines the public protection of the BUS configuration bits (enable, ready, divider).
  [1] SYSPUBC — Defines the public protection of the SYS configuration bits (enable, ready, divider).
  [0] MODPUBC — Defines the public protection of the MOD configuration bits (enable, ready, divider).
0x17C4 PRIVCFGCR4 wo — RCC privilege configuration register4
  [13] NOCPVC — Defines the privilege protection of the NOC configuration bits (enable, ready, divider).
  [n+7] APB{n}PVC (n=1..5) — Defines the privilege protection of the APB{n} configuration bits (enable, ready, divider).
  [n+2] AHB{n}PVC (n=1..5) — Defines the privilege protection of the AHB{n} configuration bits (enable, ready, divider).
  [2] AHBMPVC — Defines the privilege protection of the AHBM configuration bits (enable, ready, divider).
  [1] ACLKNCPVC — Defines the privilege protection of the ACLKNC configuration bits (enable, ready, divider).
  [0] ACLKNPVC — Defines the privilege protection of the ACLKN configuration bits (enable, ready, divider).
0x17CC PUBCFGCR4 wo — RCC public configuration register4
  [13] NOCPUBC — Defines the public protection of the NOC configuration bits (enable, ready, divider).
  [n+7] APB{n}PUBC (n=1..5) — Defines the public protection of the APB{n} configuration bits (enable, ready, divider).
  [n+2] AHB{n}PUBC (n=1..5) — Defines the public protection of the AHB{n} configuration bits (enable, ready, divider).
  [2] AHBMPUBC — Defines the public protection of the AHBM configuration bits (enable, ready, divider).
  [1] ACLKNCPUBC — Defines the public protection of the ACLKNC configuration bits (enable, ready, divider).
  [0] ACLKNPUBC — Defines the public protection of the ACLKN configuration bits (enable, ready, divider).
0x17D0 PUBCFGCR5 wo — RCC public configuration register4
  [11] VENCRAMPUBC — Defines the public protection of the VENCRAM configuration bits (enable, ready, divider).
  [10] CACHEAXIRAMPUBC — Defines the public protection of the NPUCACHERAM configuration bits (enable, ready, divider).
  [9] FLEXRAMPUBC — Defines the public protection of the FLEXRAM configuration bits (enable, ready, divider).
  [8] AXISRAM2PUBC — Defines the public protection of the AXISRAM2 configuration bits (enable, ready, divider).
  [7] AXISRAM1PUBC — Defines the public protection of the AXISRAM1 configuration bits (enable, ready, divider).
  [6] BKPSRAMPUBC — Defines the public protection of the BKPSRAM configuration bits (enable, ready, divider).
  [5] AHBSRAM2PUBC — Defines the public protection of the AHBSRAM2 configuration bits (enable, ready, divider).
  [4] AHBSRAM1PUBC — Defines the public protection of the AHBSRAM1 configuration bits (enable, ready, divider).
  [n-3] AXISRAM{n}PUBC (n=3..6) — Defines the public protection of the AXISRAM{n} configuration bits (enable, ready, divider).
